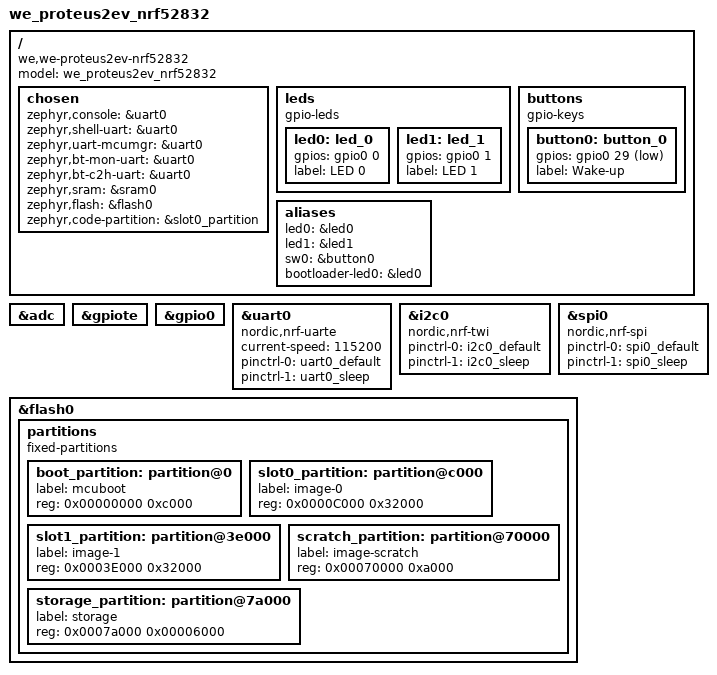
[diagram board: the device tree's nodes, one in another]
/* Copyright (c) 2022 Nordic Semiconductor ASA */
/* SPDX-License-Identifier: Apache-2.0 */

/dts-v1/;
#include <nordic/nrf52832_ciaa.dtsi>
#include "we_proteus2ev_nrf52832-pinctrl.dtsi"

/ {
	model = "we_proteus2ev_nrf52832";
	compatible = "we,we-proteus2ev-nrf52832";

	chosen {
		zephyr,console = &uart0;
		zephyr,shell-uart = &uart0;
		zephyr,uart-mcumgr = &uart0;
		zephyr,bt-mon-uart = &uart0;
		zephyr,bt-c2h-uart = &uart0;
		zephyr,sram = &sram0;
		zephyr,flash = &flash0;
		zephyr,code-partition = &slot0_partition;
	};

	leds {
		compatible = "gpio-leds";
		led0: led_0 {
			gpios = <&gpio0 0 GPIO_ACTIVE_HIGH>;
			label = "LED 0";
		};
		led1: led_1 {
			gpios = <&gpio0 1 GPIO_ACTIVE_HIGH>;
			label = "LED 1";
		};
	};

	buttons {
		compatible = "gpio-keys";
		button0: button_0 {
			gpios = <&gpio0 29 (GPIO_PULL_UP | GPIO_ACTIVE_LOW)>;
			label = "Wake-up";
		};
	};

	/* These aliases are provided for compatibility with samples */
	aliases {
		led0 = &led0;
		led1 = &led1;
		sw0 = &button0;
		bootloader-led0 = &led0;
	};
};

&adc {
	status = "okay";
};

&gpiote {
	status = "okay";
};

&gpio0 {
	status = "okay";
};

&uart0 {
	compatible = "nordic,nrf-uarte";
	status = "okay";
	current-speed = <115200>;
	pinctrl-0 = <&uart0_default>;
	pinctrl-1 = <&uart0_sleep>;
	pinctrl-names = "default", "sleep";
};

&i2c0 {
	compatible = "nordic,nrf-twi";
	/* Cannot be used together with spi1. */
	/* status = "okay"; */
	pinctrl-0 = <&i2c0_default>;
	pinctrl-1 = <&i2c0_sleep>;
	pinctrl-names = "default", "sleep";
};

&spi0 {
	compatible = "nordic,nrf-spi";
	/* Cannot be used together with i2c0. */
	/* status = "okay"; */
	pinctrl-0 = <&spi0_default>;
	pinctrl-1 = <&spi0_sleep>;
	pinctrl-names = "default", "sleep";
};

&flash0 {
	partitions {
		compatible = "fixed-partitions";
		#address-cells = <1>;
		#size-cells = <1>;

		boot_partition: partition@0 {
			label = "mcuboot";
			reg = <0x00000000 0xc000>;
		};
		slot0_partition: partition@c000 {
			label = "image-0";
			reg = <0x0000C000 0x32000>;
		};
		slot1_partition: partition@3e000 {
			label = "image-1";
			reg = <0x0003E000 0x32000>;
		};
		scratch_partition: partition@70000 {
			label = "image-scratch";
			reg = <0x00070000 0xa000>;
		};
		storage_partition: partition@7a000 {
			label = "storage";
			reg = <0x0007a000 0x00006000>;
		};
	};
};
